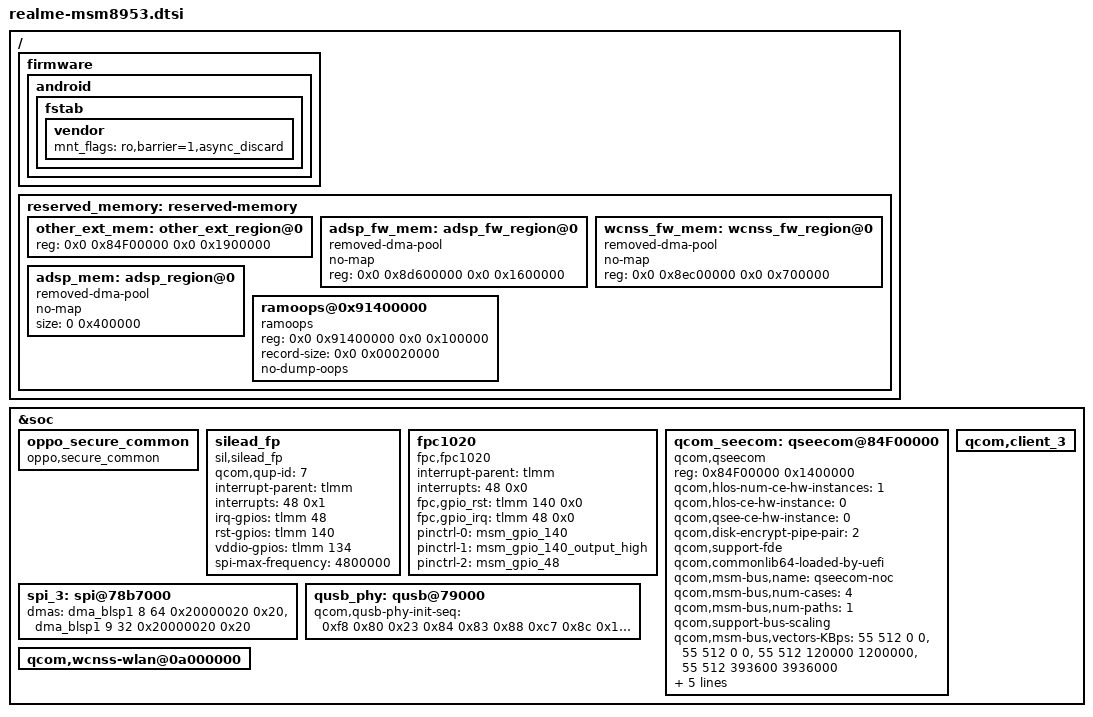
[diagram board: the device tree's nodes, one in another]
/*
 * Copyright (c) 2015-2018, The Linux Foundation. All rights reserved.
 *
 * This program is free software; you can redistribute it and/or modify
 * it under the terms of the GNU General Public License version 2 and
 * only version 2 as published by the Free Software Foundation.
 *
 * This program is distributed in the hope that it will be useful,
 * but WITHOUT ANY WARRANTY; without even the implied warranty of
 * MERCHANTABILITY or FITNESS FOR A PARTICULAR PURPOSE.  See the
 * GNU General Public License for more details.
 */

 / {
	firmware: firmware {
		android {
			fstab {
				vendor {
					mnt_flags = "ro,barrier=1,async_discard";
				};
			};
		};
	};

	reserved_memory: reserved-memory {

		other_ext_mem: other_ext_region@0 {
			reg = <0x0 0x84F00000 0x0 0x1900000>;
		};

		adsp_fw_mem: adsp_fw_region@0 {
			compatible = "removed-dma-pool";
			no-map;
			reg = <0x0 0x8d600000 0x0 0x1600000>;
		};

		wcnss_fw_mem: wcnss_fw_region@0 {
			compatible = "removed-dma-pool";
			no-map;
			reg = <0x0 0x8ec00000 0x0 0x700000>;
		};

		adsp_mem: adsp_region@0 {
			compatible = "removed-dma-pool";
			no-map;
			size = <0 0x400000>;
		};

		ramoops@0x91400000 {
			compatible = "ramoops";
			reg = <0x0 0x91400000 0x0 0x100000>;
			record-size = <0x0 0x00020000>;
			no-dump-oops;
		};		
	};
 };


&soc {
	oppo_secure_common {
	    compatible = "oppo,secure_common";
	};

	silead_fp {
		compatible = "sil,silead_fp";
		qcom,qup-id = <7>;
		interrupt-parent = <&tlmm>;
		interrupts = <48 0x1>;
		irq-gpios = <&tlmm 48 0x00>;
		rst-gpios = <&tlmm 140 0x00>;
		vddio-gpios = <&tlmm 134 0x00>;
		spi-max-frequency = <4800000>;
		status="ok";
	};

	fpc1020 {
		status = "ok";
		compatible = "fpc,fpc1020";
		interrupt-parent = <&tlmm>;
		interrupts = <48 0x0>;
		fpc,gpio_rst    = <&tlmm 140 0x0>;
		fpc,gpio_irq    = <&tlmm 48 0x0>;

		pinctrl-names = "fpc1020_reset_reset",
			"fpc1020_reset_active",
			"fpc1020_irq_active";

		pinctrl-0 = <&msm_gpio_140>;
		pinctrl-1 = <&msm_gpio_140_output_high>;
		pinctrl-2 = <&msm_gpio_48>;
	};

	/delete-node/ qseecom@85b00000;

	qcom_seecom: qseecom@84F00000 {
		compatible = "qcom,qseecom";
		reg = <0x84F00000 0x1400000>;
		reg-names = "secapp-region";
		qcom,hlos-num-ce-hw-instances = <1>;
		qcom,hlos-ce-hw-instance = <0>;
		qcom,qsee-ce-hw-instance = <0>;
		qcom,disk-encrypt-pipe-pair = <2>;
		qcom,support-fde;
		qcom,commonlib64-loaded-by-uefi;
		qcom,msm-bus,name = "qseecom-noc";
		qcom,msm-bus,num-cases = <4>;
		qcom,msm-bus,num-paths = <1>;
		qcom,support-bus-scaling;
		qcom,msm-bus,vectors-KBps =
			<55 512 0 0>,
			<55 512 0 0>,
			<55 512 120000 1200000>,
			<55 512 393600 3936000>;
		clocks = <&clock_gcc clk_crypto_clk_src>,
			 <&clock_gcc clk_gcc_crypto_clk>,
			 <&clock_gcc clk_gcc_crypto_ahb_clk>,
			 <&clock_gcc clk_gcc_crypto_axi_clk>;
		clock-names = "core_clk_src", "core_clk",
				"iface_clk", "bus_clk";
		qcom,ce-opp-freq = <100000000>;
		status = "okay";
	};

	spi_3: spi@78b7000 { /* BLSP1 QUP3 */
		dmas = <&dma_blsp1 8 64 0x20000020 0x20>,
			<&dma_blsp1 9 32 0x20000020 0x20>;
		dma-names = "tx", "rx";
	};

	qcom,client_3 {
		/delete-property/ qcom,allocate-boot-time;
	};

	qusb_phy: qusb@79000 {
		qcom,qusb-phy-init-seq = <0xf8 0x80
					0x23 0x84
					0x83 0x88
					0xc7 0x8c
					0x14 0x9c
					0x30 0x08
					0x79 0x0c
					0x21 0x10
					0x00 0x90
					0x9f 0x1c
					0x00 0x18>;
	};

	qcom,wcnss-wlan@0a000000 {
		/delete-property/ qcom,has-autodetect-xo;
	};
};
